# RP2040 register map
Vendor: Raspberry Pi; File version: 0.1
CPU: CM0PLUS r0p1, little endian, MPU, no FPU, VTOR, 2 interrupt priority bits, 26 interrupts
Registers are 32-bit, read-write, reset 0x0 unless marked. A register's access mark holds for its fields unless they carry their own. Offsets are from the block's base; [hi:lo] are bit positions; {n}, {i} and the like mark numbered series; 'fields as' and 'values as' point back to an identical list.

## WATCHDOG
Base 0x40058000
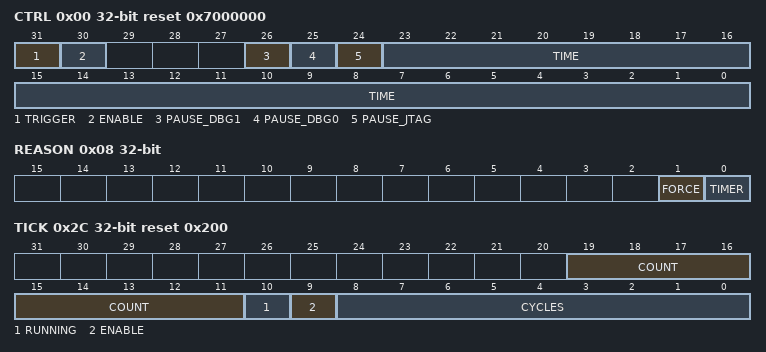
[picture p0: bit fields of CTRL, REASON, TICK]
0x00 CTRL access per field reset 0x7000000 — Watchdog control. The rst_wdsel register determines which subsystems are reset when the watchdog is triggered. The watchdog can be triggered in software.
  [31] TRIGGER rw write-1-sets — Trigger a watchdog reset
  [30] ENABLE rw — When not enabled the watchdog timer is paused
  [26] PAUSE_DBG1 rw — Pause the watchdog timer when processor 1 is in debug mode
  [25] PAUSE_DBG0 rw — Pause the watchdog timer when processor 0 is in debug mode
  [24] PAUSE_JTAG rw — Pause the watchdog timer when JTAG is accessing the bus fabric
  [23:0] TIME ro — Indicates the number of ticks / 2 (see errata RP2040-E1) before a watchdog reset will be triggered
0x04 LOAD wo — Load the watchdog timer. The maximum setting is 0xffffff which corresponds to 0xffffff / 2 ticks before triggering a watchdog reset (see errata RP2040-E1).
  [23:0] LOAD
0x08 REASON ro — Logs the reason for the last reset. Both bits are zero for the case of a hardware reset.
  [1] FORCE, [0] TIMER
{0xC+4i} SCRATCH{i} (i=0..7) — Scratch register. Information persists through soft reset of the chip.
0x2C TICK access per field reset 0x200 — Controls the tick generator
  [19:11] COUNT ro — Count down timer: the remaining number clk_tick cycles before the next tick is generated.
  [10] RUNNING ro — Is the tick generator running?
  [9] ENABLE rw — start / stop tick generation
  [8:0] CYCLES rw — Total number of clk_tick cycles before the next tick.

## RTC — Register block to control RTC
Base 0x4005C000
0x00 CLKDIV_M1 — Divider minus 1 for the 1 second counter. Safe to change the value when RTC is not enabled.
  [15:0] CLKDIV_M1
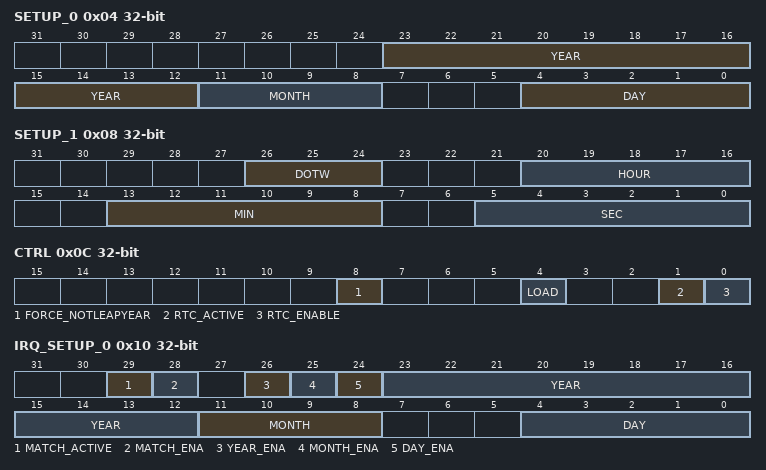
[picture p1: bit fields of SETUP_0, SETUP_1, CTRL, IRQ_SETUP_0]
0x04 SETUP_0 — RTC setup register 0
  [23:12] YEAR
  [11:8] MONTH — Month (1..12)
  [4:0] DAY — Day of the month (1..31)
0x08 SETUP_1 — RTC setup register 1
  [26:24] DOTW — Day of the week: 1-Monday...0-Sunday ISO 8601 mod 7
  [20:16] HOUR — Hours
  [13:8] MIN — Minutes
  [5:0] SEC — Seconds
0x0C CTRL access per field — RTC Control and status
  [8] FORCE_NOTLEAPYEAR rw — If set, leapyear is forced off. Useful for years divisible by 100 but not by 400
  [4] LOAD rw write-1-sets — Load RTC
  [1] RTC_ACTIVE ro — RTC enabled (running)
  [0] RTC_ENABLE rw — Enable RTC
0x10 IRQ_SETUP_0 access per field — Interrupt setup register 0
  [29] MATCH_ACTIVE ro
  [28] MATCH_ENA rw — Global match enable. Don't change any other value while this one is enabled
  [26] YEAR_ENA rw — Enable year matching
  [25] MONTH_ENA rw — Enable month matching
  [24] DAY_ENA rw — Enable day matching
  [23:12] YEAR rw
  [11:8] MONTH rw — Month (1..12)
  [4:0] DAY rw — Day of the month (1..31)
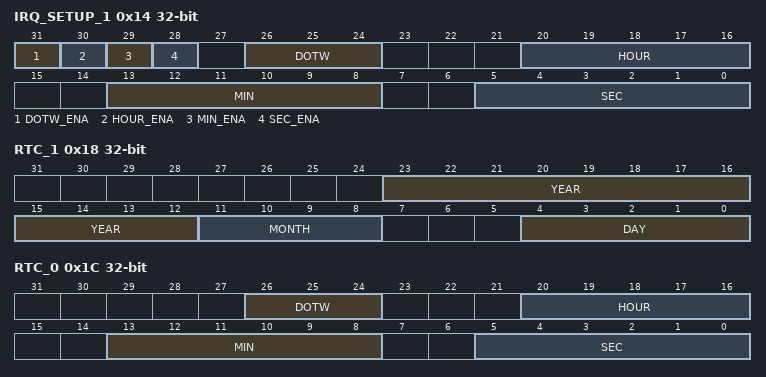
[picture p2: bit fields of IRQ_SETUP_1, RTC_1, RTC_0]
0x14 IRQ_SETUP_1 — Interrupt setup register 1
  [31] DOTW_ENA — Enable day of the week matching
  [30] HOUR_ENA — Enable hour matching
  [29] MIN_ENA — Enable minute matching
  [28] SEC_ENA — Enable second matching
  [26:24] DOTW — Day of the week
  [20:16] HOUR — Hours
  [13:8] MIN — Minutes
  [5:0] SEC — Seconds
0x18 RTC_1 ro — RTC register 1.
  fields as SETUP_0
0x1C RTC_0 ro — RTC register 0. Read this before RTC 1!
  [26:24] DOTW — Day of the week
  [20:16] HOUR — Hours
  [13:8] MIN — Minutes
  [5:0] SEC — Seconds
0x20 INTR ro — Raw Interrupts
  [0] RTC
0x24 INTE — Interrupt Enable
  [0] RTC
0x28 INTF — Interrupt Force
  [0] RTC
0x2C INTS ro — Interrupt status after masking & forcing
  [0] RTC

## VREG_AND_CHIP_RESET — control and status for on-chip voltage regulator and chip level reset subsystem
Base 0x40064000
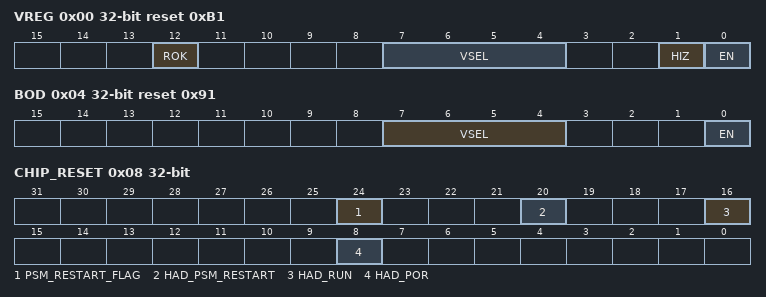
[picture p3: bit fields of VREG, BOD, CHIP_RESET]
0x00 VREG access per field reset 0xB1 — Voltage regulator control and status
  [12] ROK ro — regulation status. 0=not in regulation, 1=in regulation
  [7:4] VSEL rw — output voltage select. 0000 to 0101 - 0.80V. 0110 - 0.85V. 0111 - 0.90V. 1000 - 0.95V. 1001 - 1.00V. 1010 - 1.05V. 1011 - 1.10V (default). 1100 - 1.15V. 1101 - 1.20V. 1110 - 1.25V. 1111 - 1.30V
  [1] HIZ rw — high impedance mode select. 0=not in high impedance mode, 1=in high impedance mode
  [0] EN rw — enable. 0=not enabled, 1=enabled
0x04 BOD reset 0x91 — brown-out detection control
  [7:4] VSEL — threshold select. 0000 - 0.473V. 0001 - 0.516V. 0010 - 0.559V. 0011 - 0.602V. 0100 - 0.645V. 0101 - 0.688V. 0110 - 0.731V. 0111 - 0.774V. 1000 - 0.817V. 1001 - 0.860V (default). 1010 - 0.903V. 1011 - 0.946V. 1100 - 0.989V. 1101 - 1.032V. 1110 - 1.075V. 1111 - 1.118V
  [0] EN — enable. 0=not enabled, 1=enabled
0x08 CHIP_RESET access per field — Chip reset control and status
  [24] PSM_RESTART_FLAG rw write-1-clears — This is set by psm_restart from the debugger. Its purpose is to branch bootcode to a safe mode when the debugger has issued a psm_restart in order to recover from a boot lock-up. In the safe mode the debugger can repair the boot code, clear this flag then reboot the processor.
  [20] HAD_PSM_RESTART ro — Last reset was from the debug port
  [16] HAD_RUN ro — Last reset was from the RUN pin
  [8] HAD_POR ro — Last reset was from the power-on reset or brown-out detection blocks

## TBMAN — Testbench manager. Allows the programmer to know what platform their software is running on.
Base 0x4006C000
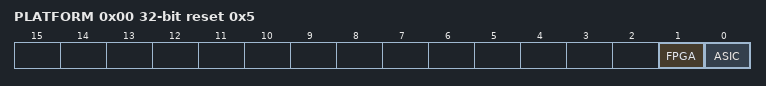
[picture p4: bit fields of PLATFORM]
0x00 PLATFORM ro reset 0x5 — Indicates the type of platform in use
  [1] FPGA — Indicates the platform is an FPGA
  [0] ASIC — Indicates the platform is an ASIC
